# PIC32MZ1064DAK176 device description
Architecture: MIPS; Family: PIC32MZDA; Series: PIC32MZ
Registers are 32-bit, read-write, no defined reset value unless marked. A register's access mark holds for its fields unless they carry their own. Offsets are from the block's base; [hi:lo] are bit positions; {n}, {i} and the like mark numbered series; 'fields as' and 'values as' point back to an identical list.

## DSCTRL
Instances: DSCTRL 0x1f8c0200 in periph_pb6_std
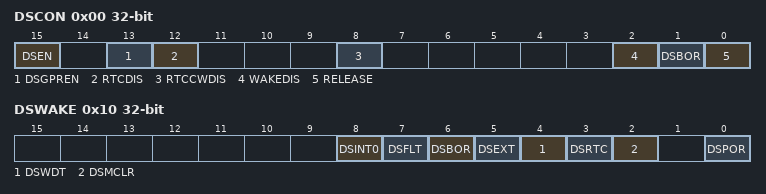
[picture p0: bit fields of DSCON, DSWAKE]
0x00 DSCON
  [15] DSEN, [13] DSGPREN, [12] RTCDIS, [8] RTCCWDIS, [2] WAKEDIS, [1] DSBOR, [0] RELEASE
0x10 DSWAKE
  [8] DSINT0, [7] DSFLT, [6] DSBOR, [5] DSEXT, [4] DSWDT, [3] DSRTC, [2] DSMCLR, [0] DSPOR
0x20 DSGPR0
  [31:0] DSGPR
{0x3C+4i} DSGPR{i} (i=1..32)
  [31:0] DSGPR

## EBI
Instances: EBI 0x1f8e1014 in periph_indep
{0x0+4i} EBICS{i} (i=0..3) — External Bus Interface Chip Select Register
  [31:16] CSADDR — Base Address for Device bits
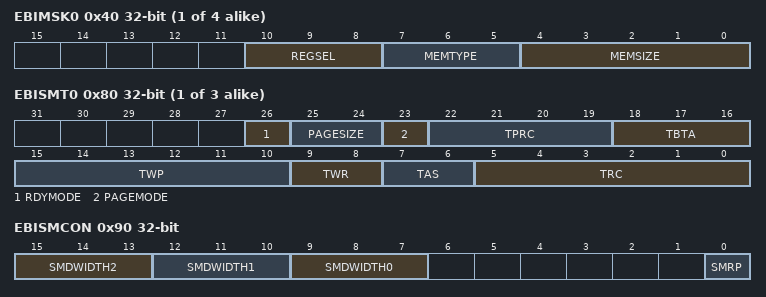
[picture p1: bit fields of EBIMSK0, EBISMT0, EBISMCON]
{0x40+4i} EBIMSK{i} (i=0..3) — External Bus Interface Address Mask Register
  [10:8] REGSEL — Timing Register Set for Chip Select 'x' bits
    2=Use EBISMT2; 1=Use EBISMT1; 0=Use EBISMT0
  [7:5] MEMTYPE — Select Memory Type for Chip Select 'x' bits
    2=NOR-Flash; 1=SRAM
  [4:0] MEMSIZE — Select Memory Size for Chip Select 'x' bits
    9=16 MB; 8=8 MB; 7=4 MB; 6=2 MB; 5=1 MB; 4=512 KB; 3=256 KB; 2=128 KB; 1=64 KB (smaller memories alias within this range); 0=Chip Select is not used
{0x80+4i} EBISMT{i} (i=0..2) — External Bus Interface Static Memory Timing Register
  [26] RDYMODE — Data Ready Device Select bit
    1=EBIRDYx input is used; 0=EBIRDYx input is not used
  [25:24] PAGESIZE — Page Size for Page Mode Device bits
    3=32-word page; 2=16-word page; 1=8-word page; 0=4-word page
  [23] PAGEMODE — Memory Device Page Mode Support bit
    1=Device supports Page mode; 0=Device does not support Page mode
  [22:19] TPRC — Page Mode Read Cycle Time bits
  [18:16] TBTA — Data Bus Turnaround Time bits
  [15:10] TWP — Write Pulse Width bits
  [9:8] TWR — Write Address/Data Hold Time bits
  [7:6] TAS — Write Address Setup Time bits
  [5:0] TRC — Read Cycle Time bits
0x8C EBIFTRPD — External Bus Interface Flash Timing Register
  [31:0] TRPD — Flash Timing bits
0x90 EBISMCON — External Bus Interface Static Memory Control Register
  [15:13] SMDWIDTH2 — Static Memory Width for Register EBISMT2 bits
    4=8 bits; 0=16 bits
  [12:10] SMDWIDTH1 — Static Memory Width for Register EBISMT1 bits
    4=8 bits; 0=16 bits
  [9:7] SMDWIDTH0 — Static Memory Width for Register EBISMT0 bits
    4=8 bits; 0=16 bits
  [0] SMRP — Flash Reset/Power-down mode Select bit
    1=Flash is taken out of Power-down mode; 0=Flash is forced into Power-down mode

## GPU
Instances: GPU 0x1f8eb000 in periph_indep
0x00 GPUBASEADDR

## HLVD
Instances: HLVD 0x1f801800 in periph_pb1_std
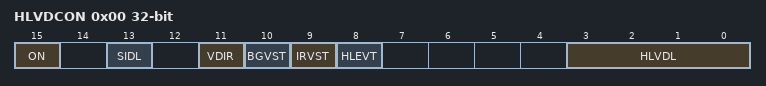
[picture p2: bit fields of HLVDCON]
0x00 HLVDCON — High/Low-Voltage Detect Control Register
  [15] ON — HLVD Module Enable bit
    1=HLVD module is enabled; 0=HLVD module is disabled
  [13] SIDL
  [11] VDIR — Voltage Change Direction Select bit
    1=Event occurs when voltage equals or exceeds the trip point (HLVDL); 0=Event occurs when voltage equals or falls below the trip point (HLVDL)
  [10] BGVST — Band Gap Reference Voltages Stable Status bit
    1=Indicates internal band gap voltage references is stable; 0=Indicates internal band gap voltage reference is not stable
  [9] IRVST
  [8] HLEVT — High/Low-Voltage Detection Event Status bit
    1=Indicates HLVD Event is active; 0=Indicates HLVD Event is not active
  [3:0] HLVDL — High/Low-Voltage Detection Limit Select bits(1)
    15=Selects analog input on HLVDIN; {v}=Selects trip point {v} (v=4..14); {v}=Reserved; do not use (v=0..3)

## ICAP
Instances: ICAP 0x1f842000 in periph_pb3_std
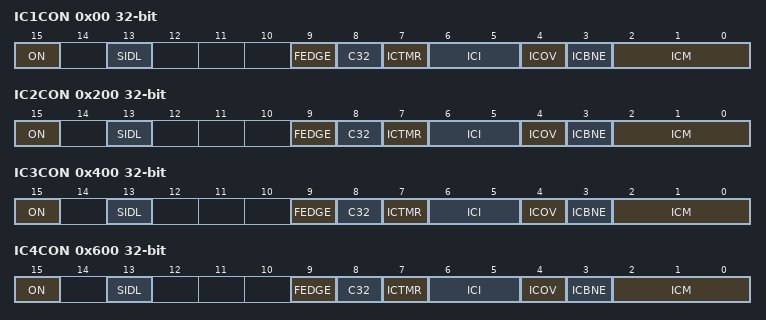
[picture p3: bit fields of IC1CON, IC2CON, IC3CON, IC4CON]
0x00 IC1CON — Input Capture x Control Register
  [15] ON — Input Capture Module Enable bit
    1=Module is enabled; 0=Disable and reset module
  [13] SIDL — Stop in Idle Control bit
    1=Halt in CPU Idle mode; 0=Continue to operate in CPU Idle mode
  [9] FEDGE — First Capture Edge Select bit
    1=Capture rising edge first; 0=Capture falling edge first
  [8] C32 — 32-bit Capture Select bit
    1=32-bit timer resource capture; 0=16-bit timer resource capture
  [7] ICTMR — Timer Select bit
    0=Timery is the counter source for capture; 1=Timerx is the counter source for capture
  [6:5] ICI — Interrupt Control bits
    3=Interrupt on every fourth capture event; 2=Interrupt on every third capture event; 1=Interrupt on every second capture event; 0=Interrupt on every capture event
  [4] ICOV — Input Capture Overflow Status Flag bit
    1=Input capture overflow is occurred; 0=No input capture overflow is occurred
  [3] ICBNE — Input Capture Buffer Not Empty Status bit
    1=Input capture buffer is not empty; at least one more capture value can be read; 0=Input capture buffer is empty
  [2:0] ICM — Input Capture Mode Select bits
    7=Interrupt-Only mode (only supported while in Sleep mode or Idle mode); 6=Simple Capture Event mode every edge; 5=Prescaled Capture Event mode every sixteenth rising edge; 4=Prescaled Capture Event mode every fourth rising edge; 3=Simple Capture Event mode every rising edge; 2=Simple Capture Event mode every falling edge; 1=Edge Detect mode every edge (rising and falling); 0=Input Capture module is disabled
0x10 IC1BUF ro
0x200 IC2CON — Input Capture x Control Register
  fields as IC1CON
0x210 IC2BUF ro
0x400 IC3CON — Input Capture x Control Register
  fields as IC1CON
0x410 IC3BUF ro
0x600 IC4CON — Input Capture x Control Register
  fields as IC1CON
0x610 IC4BUF ro
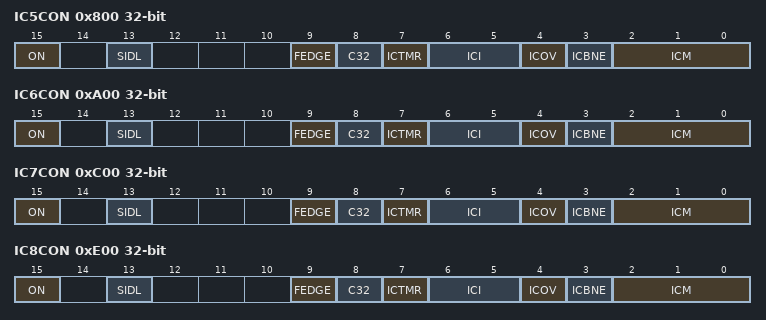
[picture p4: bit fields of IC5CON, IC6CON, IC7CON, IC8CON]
0x800 IC5CON — Input Capture x Control Register
  fields as IC1CON
0x810 IC5BUF ro
0xA00 IC6CON — Input Capture x Control Register
  fields as IC1CON
0xA10 IC6BUF ro
0xC00 IC7CON — Input Capture x Control Register
  fields as IC1CON
0xC10 IC7BUF ro
0xE00 IC8CON — Input Capture x Control Register
  fields as IC1CON
0xE10 IC8BUF ro
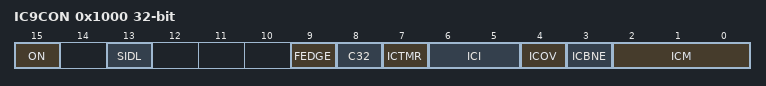
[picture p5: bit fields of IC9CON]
0x1000 IC9CON — Input Capture x Control Register
  fields as IC1CON
0x1010 IC9BUF ro

## Notices in the file
Copyright (c) 2017 Microchip Technology Inc.
SPDX-License-Identifier: Apache-2.0
Licensed under the Apache License, Version 2.0 (the "License");
you may not use this file except in compliance with the License.
You may obtain a copy of the License at
http://www.apache.org/licenses/LICENSE-2.0
Unless required by applicable law or agreed to in writing, software
distributed under the License is distributed on an "AS IS" BASIS,
WITHOUT WARRANTIES OR CONDITIONS OF ANY KIND, either express or implied.
See the License for the specific language governing permissions and
limitations under the License.
